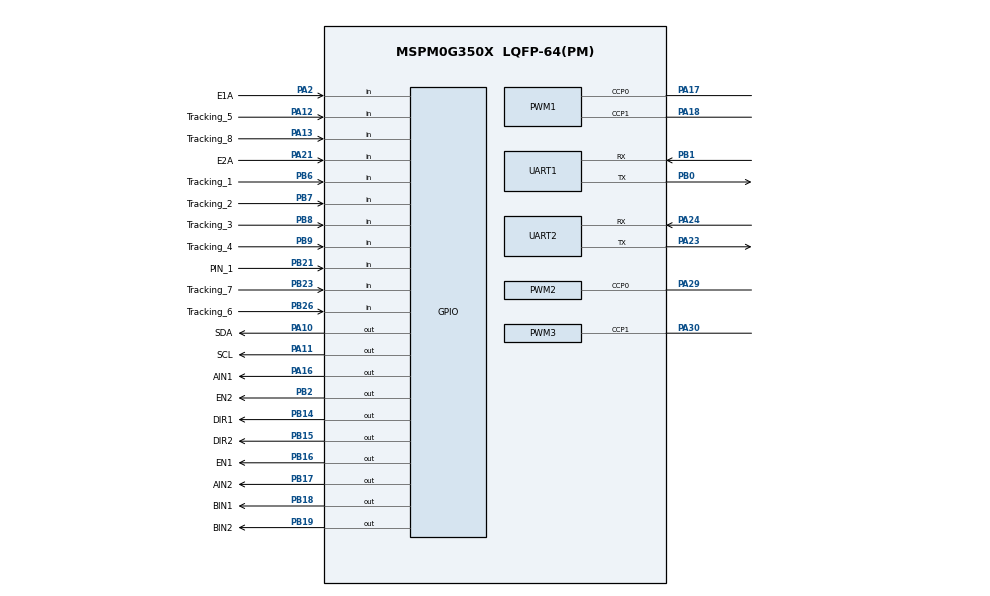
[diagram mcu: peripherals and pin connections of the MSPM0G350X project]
/**
 * @cliArgs --device "MSPM0G350X" --part "Default" --package "LQFP-64(PM)" --product "mspm0_sdk@2.05.01.01"
 * @versions {"tool":"1.24.1+4189"}
 */

/**
 * Import the modules used in this configuration.
 */
const GPIO    = scripting.addModule("/ti/driverlib/GPIO", {}, false);
const GPIO1   = GPIO.addInstance();
const GPIO2   = GPIO.addInstance();
const GPIO3   = GPIO.addInstance();
const GPIO4   = GPIO.addInstance();
const GPIO5   = GPIO.addInstance();
const GPIO6   = GPIO.addInstance();
const PWM     = scripting.addModule("/ti/driverlib/PWM", {}, false);
const PWM1    = PWM.addInstance();
const PWM2    = PWM.addInstance();
const PWM3    = PWM.addInstance();
const SYSCTL  = scripting.addModule("/ti/driverlib/SYSCTL");
const SYSTICK = scripting.addModule("/ti/driverlib/SYSTICK");
const TIMER   = scripting.addModule("/ti/driverlib/TIMER", {}, false);
const TIMER1  = TIMER.addInstance();
const UART    = scripting.addModule("/ti/driverlib/UART", {}, false);
const UART1   = UART.addInstance();
const UART2   = UART.addInstance();

/**
 * Write custom configuration values to the imported modules.
 */
GPIO1.$name                              = "LED";
GPIO1.port                               = "PORTB";
GPIO1.associatedPins[0].internalResistor = "PULL_DOWN";
GPIO1.associatedPins[0].$name            = "LED0";
GPIO1.associatedPins[0].assignedPin      = "22";

const Board = scripting.addModule("/ti/driverlib/Board", {}, false);

GPIO2.$name                              = "SMotor_IO";
GPIO2.associatedPins.create(4);
GPIO2.associatedPins[0].$name            = "DIR1";
GPIO2.associatedPins[0].internalResistor = "PULL_DOWN";
GPIO2.associatedPins[0].pin.$assign      = "PB14";
GPIO2.associatedPins[1].$name            = "DIR2";
GPIO2.associatedPins[1].internalResistor = "PULL_DOWN";
GPIO2.associatedPins[1].pin.$assign      = "PB15";
GPIO2.associatedPins[2].$name            = "EN1";
GPIO2.associatedPins[2].pin.$assign      = "PB16";
GPIO2.associatedPins[3].$name            = "EN2";
GPIO2.associatedPins[3].pin.$assign      = "PB2";

GPIO3.$name                               = "Motor_IO";
GPIO3.associatedPins.create(6);
GPIO3.associatedPins[0].$name             = "AIN1";
GPIO3.associatedPins[0].internalResistor  = "PULL_DOWN";
GPIO3.associatedPins[0].pin.$assign       = "PA16";
GPIO3.associatedPins[1].$name             = "AIN2";
GPIO3.associatedPins[1].internalResistor  = "PULL_DOWN";
GPIO3.associatedPins[1].pin.$assign       = "PB17";
GPIO3.associatedPins[2].$name             = "BIN1";
GPIO3.associatedPins[2].internalResistor  = "PULL_DOWN";
GPIO3.associatedPins[2].pin.$assign       = "PB18";
GPIO3.associatedPins[3].$name             = "BIN2";
GPIO3.associatedPins[3].internalResistor  = "PULL_DOWN";
GPIO3.associatedPins[3].pin.$assign       = "PB19";
GPIO3.associatedPins[4].$name             = "E1A";
GPIO3.associatedPins[4].direction         = "INPUT";
GPIO3.associatedPins[4].interruptEn       = true;
GPIO3.associatedPins[4].interruptPriority = "0";
GPIO3.associatedPins[4].polarity          = "RISE";
GPIO3.associatedPins[4].inputFilter       = "3_CYCLES";
GPIO3.associatedPins[4].pin.$assign       = "PA2";
GPIO3.associatedPins[5].$name             = "E2A";
GPIO3.associatedPins[5].direction         = "INPUT";
GPIO3.associatedPins[5].interruptEn       = true;
GPIO3.associatedPins[5].interruptPriority = "0";
GPIO3.associatedPins[5].polarity          = "RISE";
GPIO3.associatedPins[5].inputFilter       = "3_CYCLES";
GPIO3.associatedPins[5].pin.$assign       = "PA21";

GPIO4.$name                              = "Key";
GPIO4.associatedPins[0].$name            = "PIN_1";
GPIO4.associatedPins[0].direction        = "INPUT";
GPIO4.associatedPins[0].internalResistor = "PULL_UP";
GPIO4.associatedPins[0].pin.$assign      = "PB21";

GPIO5.$name                              = "Tracking";
GPIO5.associatedPins.create(8);
GPIO5.associatedPins[0].$name            = "Tracking_1";
GPIO5.associatedPins[0].direction        = "INPUT";
GPIO5.associatedPins[0].internalResistor = "PULL_DOWN";
GPIO5.associatedPins[0].pin.$assign      = "PB6";
GPIO5.associatedPins[1].$name            = "Tracking_2";
GPIO5.associatedPins[1].internalResistor = "PULL_DOWN";
GPIO5.associatedPins[1].direction        = "INPUT";
GPIO5.associatedPins[1].pin.$assign      = "PB7";
GPIO5.associatedPins[2].$name            = "Tracking_3";
GPIO5.associatedPins[2].internalResistor = "PULL_DOWN";
GPIO5.associatedPins[2].direction        = "INPUT";
GPIO5.associatedPins[2].pin.$assign      = "PB8";
GPIO5.associatedPins[3].$name            = "Tracking_4";
GPIO5.associatedPins[3].internalResistor = "PULL_DOWN";
GPIO5.associatedPins[3].direction        = "INPUT";
GPIO5.associatedPins[3].pin.$assign      = "PB9";
GPIO5.associatedPins[4].$name            = "Tracking_5";
GPIO5.associatedPins[4].internalResistor = "PULL_DOWN";
GPIO5.associatedPins[4].direction        = "INPUT";
GPIO5.associatedPins[4].pin.$assign      = "PA12";
GPIO5.associatedPins[5].$name            = "Tracking_6";
GPIO5.associatedPins[5].internalResistor = "PULL_DOWN";
GPIO5.associatedPins[5].direction        = "INPUT";
GPIO5.associatedPins[5].pin.$assign      = "PB26";
GPIO5.associatedPins[6].$name            = "Tracking_7";
GPIO5.associatedPins[6].direction        = "INPUT";
GPIO5.associatedPins[6].internalResistor = "PULL_DOWN";
GPIO5.associatedPins[6].pin.$assign      = "PB23";
GPIO5.associatedPins[7].$name            = "Tracking_8";
GPIO5.associatedPins[7].internalResistor = "PULL_DOWN";
GPIO5.associatedPins[7].direction        = "INPUT";
GPIO5.associatedPins[7].pin.$assign      = "PA13";

GPIO6.$name                              = "OLED";
GPIO6.associatedPins.create(2);
GPIO6.associatedPins[0].$name            = "SDA";
GPIO6.associatedPins[0].internalResistor = "PULL_UP";
GPIO6.associatedPins[0].pin.$assign      = "PA10";
GPIO6.associatedPins[1].$name            = "SCL";
GPIO6.associatedPins[1].internalResistor = "PULL_UP";
GPIO6.associatedPins[1].pin.$assign      = "PA11";

PWM1.$name                              = "Motor";
PWM1.clockDivider                       = 8;
PWM1.timerStartTimer                    = true;
PWM1.pwmMode                            = "EDGE_ALIGN_UP";
PWM1.peripheral.$assign                 = "TIMG7";
PWM1.peripheral.ccp0Pin.$assign         = "PA17";
PWM1.peripheral.ccp1Pin.$assign         = "PA18";
PWM1.PWM_CHANNEL_0.$name                = "ti_driverlib_pwm_PWMTimerCC0";
PWM1.PWM_CHANNEL_0.dutyCycle            = 50;
PWM1.PWM_CHANNEL_1.$name                = "ti_driverlib_pwm_PWMTimerCC1";
PWM1.PWM_CHANNEL_1.ccValue              = 500;
PWM1.ccp0PinConfig.direction            = scripting.forceWrite("OUTPUT");
PWM1.ccp0PinConfig.hideOutputInversion  = scripting.forceWrite(false);
PWM1.ccp0PinConfig.onlyInternalResistor = scripting.forceWrite(false);
PWM1.ccp0PinConfig.passedPeripheralType = scripting.forceWrite("Digital");
PWM1.ccp0PinConfig.$name                = "ti_driverlib_gpio_GPIOPinGeneric4";
PWM1.ccp1PinConfig.direction            = scripting.forceWrite("OUTPUT");
PWM1.ccp1PinConfig.hideOutputInversion  = scripting.forceWrite(false);
PWM1.ccp1PinConfig.onlyInternalResistor = scripting.forceWrite(false);
PWM1.ccp1PinConfig.passedPeripheralType = scripting.forceWrite("Digital");
PWM1.ccp1PinConfig.$name                = "ti_driverlib_gpio_GPIOPinGeneric5";

PWM2.timerStartTimer                    = true;
PWM2.$name                              = "SMotor_1";
PWM2.ccIndex                            = [0];
PWM2.pwmMode                            = "EDGE_ALIGN_UP";
PWM2.clockDivider                       = 8;
PWM2.clockPrescale                      = 64;
PWM2.PWM_CHANNEL_0.$name                = "ti_driverlib_pwm_PWMTimerCC2";
PWM2.ccp0PinConfig.direction            = scripting.forceWrite("OUTPUT");
PWM2.ccp0PinConfig.hideOutputInversion  = scripting.forceWrite(false);
PWM2.ccp0PinConfig.onlyInternalResistor = scripting.forceWrite(false);
PWM2.ccp0PinConfig.passedPeripheralType = scripting.forceWrite("Digital");
PWM2.ccp0PinConfig.$name                = "ti_driverlib_gpio_GPIOPinGeneric6";
PWM2.peripheral.$assign                 = "TIMG6";
PWM2.peripheral.ccp0Pin.$assign         = "PA29";

PWM3.$name                              = "SMotor_2";
PWM3.ccIndex                            = [1];
PWM3.timerStartTimer                    = true;
PWM3.pwmMode                            = "EDGE_ALIGN_UP";
PWM3.clockDivider                       = 8;
PWM3.clockPrescale                      = 64;
PWM3.ccp1PinConfig.direction            = scripting.forceWrite("OUTPUT");
PWM3.ccp1PinConfig.hideOutputInversion  = scripting.forceWrite(false);
PWM3.ccp1PinConfig.onlyInternalResistor = scripting.forceWrite(false);
PWM3.ccp1PinConfig.passedPeripheralType = scripting.forceWrite("Digital");
PWM3.ccp1PinConfig.$name                = "ti_driverlib_gpio_GPIOPinGeneric1";
PWM3.peripheral.$assign                 = "TIMG8";
PWM3.peripheral.ccp1Pin.$assign         = "PA30";
PWM3.PWM_CHANNEL_1.$name                = "ti_driverlib_pwm_PWMTimerCC3";

SYSCTL.forceDefaultClkConfig = true;

SYSTICK.periodEnable    = true;
SYSTICK.interruptEnable = true;
SYSTICK.systickEnable   = true;
SYSTICK.period          = 32000;

TIMER1.$name              = "TIMER_0";
TIMER1.timerClkPrescale   = 100;
TIMER1.timerMode          = "PERIODIC";
TIMER1.interrupts         = ["ZERO"];
TIMER1.timerClkDiv        = 8;
TIMER1.timerStartTimer    = true;
TIMER1.interruptPriority  = "3";
TIMER1.timerPeriod        = "100ms";
TIMER1.peripheral.$assign = "TIMA0";

UART1.$name                            = "Debug";
UART1.peripheral.$assign               = "UART0";
UART1.peripheral.rxPin.$assign         = "PB1";
UART1.peripheral.txPin.$assign         = "PB0";
UART1.txPinConfig.direction            = scripting.forceWrite("OUTPUT");
UART1.txPinConfig.hideOutputInversion  = scripting.forceWrite(false);
UART1.txPinConfig.onlyInternalResistor = scripting.forceWrite(false);
UART1.txPinConfig.passedPeripheralType = scripting.forceWrite("Digital");
UART1.txPinConfig.$name                = "ti_driverlib_gpio_GPIOPinGeneric12";
UART1.rxPinConfig.hideOutputInversion  = scripting.forceWrite(false);
UART1.rxPinConfig.onlyInternalResistor = scripting.forceWrite(false);
UART1.rxPinConfig.passedPeripheralType = scripting.forceWrite("Digital");
UART1.rxPinConfig.$name                = "ti_driverlib_gpio_GPIOPinGeneric13";

UART2.$name                            = "K230";
UART2.targetBaudRate                   = 115200;
UART2.enabledInterrupts                = ["RX","TX"];
UART2.interruptPriority                = "0";
UART2.peripheral.$assign               = "UART2";
UART2.peripheral.rxPin.$assign         = "PA24";
UART2.peripheral.txPin.$assign         = "PA23";
UART2.txPinConfig.direction            = scripting.forceWrite("OUTPUT");
UART2.txPinConfig.hideOutputInversion  = scripting.forceWrite(false);
UART2.txPinConfig.onlyInternalResistor = scripting.forceWrite(false);
UART2.txPinConfig.passedPeripheralType = scripting.forceWrite("Digital");
UART2.txPinConfig.$name                = "ti_driverlib_gpio_GPIOPinGeneric16";
UART2.rxPinConfig.hideOutputInversion  = scripting.forceWrite(false);
UART2.rxPinConfig.onlyInternalResistor = scripting.forceWrite(false);
UART2.rxPinConfig.passedPeripheralType = scripting.forceWrite("Digital");
UART2.rxPinConfig.$name                = "ti_driverlib_gpio_GPIOPinGeneric17";

/**
 * Pinmux solution for unlocked pins/peripherals. This ensures that minor changes to the automatic solver in a future
 * version of the tool will not impact the pinmux you originally saw.  These lines can be completely deleted in order to
 * re-solve from scratch.
 */
GPIO1.associatedPins[0].pin.$suggestSolution = "PB22";
Board.peripheral.$suggestSolution            = "DEBUGSS";
Board.peripheral.swclkPin.$suggestSolution   = "PA20";
Board.peripheral.swdioPin.$suggestSolution   = "PA19";
SYSCTL.peripheral.$suggestSolution           = "SYSCTL";
